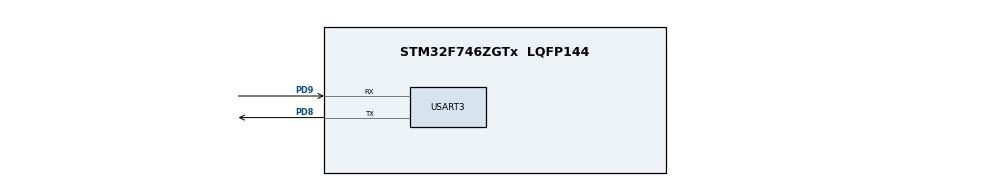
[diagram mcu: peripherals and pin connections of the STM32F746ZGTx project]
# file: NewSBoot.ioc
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CORTEX_M7.default_mode_Activation=1
Mcu.Family=STM32F7
Mcu.Name=STM32F746ZGTx
Mcu.Package=LQFP144
NVIC.PriorityGroup=NVIC_PRIORITYGROUP_4
PD8.Mode=Asynchronous
PD8.Signal=USART3_TX
PD9.Mode=Asynchronous
PD9.Signal=USART3_RX
ProjectManager.HeapSize=0x200
ProjectManager.StackSize=0x400
ProjectManager.TargetToolchain=CMake
RCC.HSE_VALUE=25000000
RCC.HSI_VALUE=16000000
RCC.LSE_VALUE=32768
RCC.USBFreq_Value=96000000
RCC.VCOOutputFreq_Value=192000000
USART3.VirtualMode-Asynchronous=VM_ASYNC
VP_MBEDTLS_VS_MBEDTLS.Mode=Enabled
board=custom

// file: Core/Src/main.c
/* USER CODE BEGIN Header */
/**
  ******************************************************************************
  * @file           : main.c
  * @brief          : Main program body
  ******************************************************************************
  * @attention
  *
  * Copyright (c) 2026 STMicroelectronics.
  * All rights reserved.
  *
  * This software is licensed under terms that can be found in the LICENSE file
  * in the root directory of this software component.
  * If no LICENSE file comes with this software, it is provided AS-IS.
  *
  ******************************************************************************
  */
/* USER CODE END Header */
#include "main.h"
#include "bootutil/bootutil.h"
#include "mbedtls.h"

/* USER CODE BEGIN Includes */
#include <stdint.h>
#include <stdio.h>
#include <string.h>
#include "cmsis_gcc.h"
#include "pk.h"
#include "sha512.h"
#include "stm32f7xx_hal.h"
#include "mbedtls/sha256.h"
#include "mbedtls/rsa.h"
#include "mbedtls/bignum.h"
#include "mbedtls/md.h"
#include "stm32f7xx_hal_flash.h"
#include "stm32f7xx_hal_flash_ex.h"
#include "flash_map_backend/flash_map_backend.h"
#include "sysflash/sysflash.h"
#include "bootutil/crypto/sha.h"
#include "bootutil/crypto/rsa.h"

/* USER CODE END Includes */

/* USER CODE BEGIN PTD */

// Pointer to function. Used for the Jump
typedef void (*pFunction ) (void);

// Struct used to read the firmware header
typedef struct
{
  /* data */
  uint32_t version;
  uint32_t size;
  uint8_t hash[32];
  uint8_t sign[256];
}Header;
/* USER CODE END PTD */

/* USER CODE BEGIN PD */

// Memory address, they are not updated automatically
#define BOOT_META 0x8018000
#define APP_ADDR_HEADER 0x8040000
#define APP_ADDR_FLASH 0x8040200

/* USER CODE END PD */

UART_HandleTypeDef huart3;

void SystemClock_Config(void);
static void MPU_Config(void);
static void MX_GPIO_Init(void);
static void MX_USART3_UART_Init(void);

/* USER CODE BEGIN 0 */

// ------------------------- Jump to Firmware  -----------------------------------------

// Jump to the firmware
void bootJump(uint32_t* AddressFlash){

  uint32_t JumpAddress;
  pFunction JumpFunction;

  printf("App Starting.. \r\n" );
  HAL_Delay(100);

  // Reset Handler function position. The first 4 bytes are the Stack Pointer
  JumpAddress = *( volatile uint32_t*) (APP_ADDR_FLASH + 4);
  JumpFunction = (pFunction) JumpAddress;

  __set_MSP(*(volatile uint32_t*) APP_ADDR_FLASH);

  HAL_DeInit();
  __disable_irq();

  JumpFunction();

}

// -------------------------- UART -----------------------------------------------

//for the print
int _write(int file, char* ptr, int len){
  int DataIdx;

  for (DataIdx = 0; DataIdx < len; DataIdx++)
  {
    HAL_UART_Transmit(&huart3, (uint8_t* )ptr++,1,100);

  }

  return len;

}

// -------------------------- Main -----------------------------------------------

/* USER CODE END 0 */

int main(void)
{

  /* MPU Configuration--------------------------------------------------------*/
  MPU_Config();

  /* MCU Configuration--------------------------------------------------------*/

  /* Reset of all peripherals, Initializes the Flash interface and the Systick. */
  HAL_Init();

  /* Configure the system clock */
  SystemClock_Config();

  /* Initialize all configured peripherals */
  MX_GPIO_Init();
  MX_USART3_UART_Init();
  MX_MBEDTLS_Init();
  /* USER CODE BEGIN 2 */

  struct boot_rsp rsp;
  printf("Boot GO called \r\n");
  int rc = boot_go(&rsp);
  boot_set_pending(0);

  if(!rc){
      bootJump((uint32_t*)(rsp.br_image_off + rsp.br_hdr->ih_hdr_size));
      printf("Something went Wrong \r\n");
  }
  else{
     printf("Wrong Image \r\n");
  }

  /* USER CODE END 2 */

  /* Infinite loop */
  while (1)
  {

  }
}

void SystemClock_Config(void)
{
  RCC_OscInitTypeDef RCC_OscInitStruct = {0};
  RCC_ClkInitTypeDef RCC_ClkInitStruct = {0};

  /** Configure the main internal regulator output voltage
  */
  __HAL_RCC_PWR_CLK_ENABLE();
  __HAL_PWR_VOLTAGESCALING_CONFIG(PWR_REGULATOR_VOLTAGE_SCALE3);

  /** Initializes the RCC Oscillators according to the specified parameters
  * in the RCC_OscInitTypeDef structure.
  */
  RCC_OscInitStruct.OscillatorType = RCC_OSCILLATORTYPE_HSI;
  RCC_OscInitStruct.HSIState = RCC_HSI_ON;
  RCC_OscInitStruct.HSICalibrationValue = RCC_HSICALIBRATION_DEFAULT;
  RCC_OscInitStruct.PLL.PLLState = RCC_PLL_NONE;
  if (HAL_RCC_OscConfig(&RCC_OscInitStruct) != HAL_OK)
  {
    Error_Handler();
  }

  /** Initializes the CPU, AHB and APB buses clocks
  */
  RCC_ClkInitStruct.ClockType = RCC_CLOCKTYPE_HCLK|RCC_CLOCKTYPE_SYSCLK
                              |RCC_CLOCKTYPE_PCLK1|RCC_CLOCKTYPE_PCLK2;
  RCC_ClkInitStruct.SYSCLKSource = RCC_SYSCLKSOURCE_HSI;
  RCC_ClkInitStruct.AHBCLKDivider = RCC_SYSCLK_DIV1;
  RCC_ClkInitStruct.APB1CLKDivider = RCC_HCLK_DIV1;
  RCC_ClkInitStruct.APB2CLKDivider = RCC_HCLK_DIV1;

  if (HAL_RCC_ClockConfig(&RCC_ClkInitStruct, FLASH_LATENCY_0) != HAL_OK)
  {
    Error_Handler();
  }
}

static void MX_USART3_UART_Init(void)
{

  huart3.Instance = USART3;
  huart3.Init.BaudRate = 115200;
  huart3.Init.WordLength = UART_WORDLENGTH_8B;
  huart3.Init.StopBits = UART_STOPBITS_1;
  huart3.Init.Parity = UART_PARITY_NONE;
  huart3.Init.Mode = UART_MODE_TX_RX;
  huart3.Init.HwFlowCtl = UART_HWCONTROL_NONE;
  huart3.Init.OverSampling = UART_OVERSAMPLING_16;
  huart3.Init.OneBitSampling = UART_ONE_BIT_SAMPLE_DISABLE;
  huart3.AdvancedInit.AdvFeatureInit = UART_ADVFEATURE_NO_INIT;
  if (HAL_UART_Init(&huart3) != HAL_OK)
  {
    Error_Handler();
  }

}

static void MX_GPIO_Init(void)
{

  /* GPIO Ports Clock Enable */
  __HAL_RCC_GPIOD_CLK_ENABLE();

}

 /* MPU Configuration */

void MPU_Config(void)
{
  MPU_Region_InitTypeDef MPU_InitStruct = {0};

  /* Disables the MPU */
  HAL_MPU_Disable();

  /** Initializes and configures the Region and the memory to be protected
  */
  MPU_InitStruct.Enable = MPU_REGION_ENABLE;
  MPU_InitStruct.Number = MPU_REGION_NUMBER0;
  MPU_InitStruct.BaseAddress = 0x0;
  MPU_InitStruct.Size = MPU_REGION_SIZE_4GB;
  MPU_InitStruct.SubRegionDisable = 0x87;
  MPU_InitStruct.TypeExtField = MPU_TEX_LEVEL0;
  MPU_InitStruct.AccessPermission = MPU_REGION_NO_ACCESS;
  MPU_InitStruct.DisableExec = MPU_INSTRUCTION_ACCESS_DISABLE;
  MPU_InitStruct.IsShareable = MPU_ACCESS_SHAREABLE;
  MPU_InitStruct.IsCacheable = MPU_ACCESS_NOT_CACHEABLE;
  MPU_InitStruct.IsBufferable = MPU_ACCESS_NOT_BUFFERABLE;

  HAL_MPU_ConfigRegion(&MPU_InitStruct);
  /* Enables the MPU */
  HAL_MPU_Enable(MPU_PRIVILEGED_DEFAULT);

}

void Error_Handler(void)
{
  __disable_irq();
  while (1)
  {
  }
}
